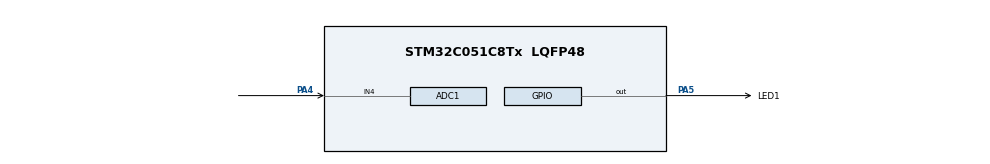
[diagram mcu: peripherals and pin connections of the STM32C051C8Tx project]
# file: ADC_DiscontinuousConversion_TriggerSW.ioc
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ADC1.Channel-0\#ChannelRegularConversion=ADC_CHANNEL_4
ADC1.Channel-1\#ChannelRegularConversion=ADC_CHANNEL_VREFINT
ADC1.ClockPrescaler=ADC_CLOCK_SYNC_PCLK_DIV4
ADC1.DiscontinuousConvMode=ENABLE
ADC1.NbrOfConversion=2
ADC1.NbrOfConversionFlag=1
ADC1.Overrun=ADC_OVR_DATA_OVERWRITTEN
ADC1.Rank-0\#ChannelRegularConversion=1
ADC1.Rank-1\#ChannelRegularConversion=2
ADC1.SamplingTime-0\#ChannelRegularConversion=ADC_SAMPLINGTIME_COMMON_1
ADC1.SamplingTime-1\#ChannelRegularConversion=ADC_SAMPLINGTIME_COMMON_1
ADC1.SamplingTimeCommon1=ADC_SAMPLETIME_160CYCLES_5
ADC1.SamplingTimeCommon2=ADC_SAMPLETIME_160CYCLES_5
ADC1.ScanConvMode=ADC_SCAN_ENABLE
ADC1.SelectedChannel=ADC_CHANNEL_4|ADC_CHANNEL_VREFINT
ADC1.Sequencer=FULLY_CONFIGURABLE
ADC1.master=1
Mcu.Family=STM32C0
Mcu.Name=STM32C051C8Tx
Mcu.Package=LQFP48
PA4.Mode=IN4
PA4.Signal=ADC1_IN4
PA5.GPIO_Label=LED1
PA5.Signal=GPIO_Output
ProjectManager.HeapSize=0x200
ProjectManager.StackSize=0x400
ProjectManager.TargetToolchain=EWARM V9.20
RCC.ADCFreq_Value=48000000
RCC.AHBFreq_Value=48000000
RCC.CortexFreq_Value=48000000
RCC.EXTERNAL_CLOCK_VALUE=12288000
RCC.HCLKFreq_Value=48000000
RCC.HSE_VALUE=8000000
RCC.HSISYSCLKDivider=RCC_HSI_DIV1
RCC.HSI_VALUE=48000000
RCC.LSE_VALUE=32768
RCC.SYSCLKFreq_VALUE=48000000
VP_ADC1_Vref_Input.Mode=IN-Vrefint
board=custom

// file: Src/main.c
/* USER CODE BEGIN Header */
/**
  ******************************************************************************
  * @file    Examples/ADC/ADC_DiscontinuousConversion_TriggerSW/Src/main.c
  * @author  MCD Application Team
  * @brief   Use ADC to convert a single channel at each SW start.
  *          Conversion performed using programming model: polling
  *          This example is based on the STM32C0xx ADC HAL API.
  ******************************************************************************
  * @attention
  *
  * <h2><center>&copy; Copyright (c) 2024 STMicroelectronics.
  * All rights reserved.</center></h2>
  *
  * This software component is licensed by ST under BSD 3-Clause license,
  * the "License"; You may not use this file except in compliance with the
  * License. You may obtain a copy of the License at:
  *                        opensource.org/licenses/BSD-3-Clause
  *
  ******************************************************************************
  */
/* USER CODE END Header */
#include "main.h"

/* USER CODE BEGIN PD */

/* Definitions of environment analog values */
  /* Value of analog reference voltage (Vref+), connected to analog voltage   */
  /* supply Vdda (unit: mV).                                                  */
  #define VDDA_APPLI                       (3300UL)

/* Definitions of data related to this example */
  /* Definition of ADCx conversions data table size */
  /* Size of array set to ADC sequencer number of ranks converted,            */
  /* to have a rank in each array address.                                    */
  #define ADC_CONVERTED_DATA_BUFFER_SIZE   (   2UL)

  /* Init variable out of expected ADC conversion data range */
  #define VAR_CONVERTED_DATA_INIT_VALUE    (__LL_ADC_DIGITAL_SCALE(LL_ADC_RESOLUTION_12B) + 1)

/* USER CODE END PD */

ADC_HandleTypeDef hadc1;

/* USER CODE BEGIN PV */

/* Variables for ADC conversion data */
__IO uint16_t uhADCxConvertedData[ADC_CONVERTED_DATA_BUFFER_SIZE]; /* ADC group regular conversion data */

/* Variables for ADC conversion data computation to physical values */
uint16_t uhADCxConvertedData_VoltageGPIO_mVolt = 0UL; /* Value of voltage calculated from ADC conversion data (unit: mV) */
uint16_t uhADCxConvertedData_VrefAnalog_mVolt  = 0UL; /* Value of analog reference voltage (Vref+), connected to analog voltage supply Vdda, calculated from ADC conversion data (unit: mV) */
uint16_t uhADCxConvertedData_VrefInt_mVolt     = 0UL; /* Value of internal voltage reference VrefInt calculated from ADC conversion data (unit: mV) */
/* USER CODE END PV */

void SystemClock_Config(void);
static void MX_GPIO_Init(void);
static void MX_ADC1_Init(void);

int main(void)
{

  /* USER CODE BEGIN 1 */
  uint32_t tmp_index;

  /* Initialize ADC group regular data buffer values */
  for (tmp_index = 0; tmp_index < ADC_CONVERTED_DATA_BUFFER_SIZE; tmp_index++)
  {
    uhADCxConvertedData[tmp_index] = VAR_CONVERTED_DATA_INIT_VALUE;
  }

  /* USER CODE END 1 */

  /* MCU Configuration--------------------------------------------------------*/

  /* Reset of all peripherals, Initializes the Flash interface and the Systick. */
  HAL_Init();

  /* Configure the system clock */
  SystemClock_Config();

  /* Initialize all configured peripherals */
  MX_GPIO_Init();
  MX_ADC1_Init();
  /* USER CODE BEGIN 2 */

  /* Initialize LED on board */
  BSP_LED_Init(LED4);

  /* Perform ADC calibration */
  if (HAL_ADCEx_Calibration_Start(&hadc1) != HAL_OK)
  {
    /* Calibration Error */
    Error_Handler();
  }

  /* USER CODE END 2 */

  /* Infinite loop */
  /* USER CODE BEGIN WHILE */
  while (1)
  {
    for (tmp_index = 0; tmp_index < ADC_CONVERTED_DATA_BUFFER_SIZE; tmp_index++)
    {
      /* Start ADC group regular conversion */
      if (HAL_ADC_Start(&hadc1) != HAL_OK)
      {
        /* ADC conversion start error */
        Error_Handler();
      }

      /* Wait for ADC conversion completed */
      if (HAL_ADC_PollForConversion(&hadc1, 10) != HAL_OK)
      {
        /* End Of Conversion flag not set on time */
        Error_Handler();
      }

      /* Retrieve ADC conversion data */
      uhADCxConvertedData[tmp_index] = HAL_ADC_GetValue(&hadc1);

      /* Toggle LED at each ADC conversion */
      BSP_LED_Toggle(LED4);
      HAL_Delay(LED_BLINK_SLOW);
    }

    /* Note: ADC group regular conversions data are stored into array         */
    /*       "uhADCxConvertedData"                                            */
    /*       (for debug: see variable content into watch window).             */

    /* Note: ADC conversion data are computed to physical values              */
    /*       into array "uhADCxConvertedData_VoltageGPIO_mVolt" using         */
    /*       ADC LL driver helper macro "__LL_ADC_CALC_DATA_TO_VOLTAGE()"     */
    /*       (for debug: see variable content with debugger)                  */

    /* For this example purpose, calculate analog reference voltage (Vref+) */
    /* from ADC conversion of internal voltage reference VrefInt.           */
    /* This voltage should correspond to value of literal "VDDA_APPLI".     */
    /* Note: This calculation can be performed when value of voltage Vref+  */
    /*       is unknown in the application                                  */
    /*       (This is not the case in this example due to target board      */
    /*       supplied by a LDO regulator providing a known constant voltage */
    /*       of value "VDDA_APPLI").                                        */
    /*       In typical case of Vref+ connected to Vdd, it allows to        */
    /*       deduce Vdd value.                                              */
    uhADCxConvertedData_VrefAnalog_mVolt = __LL_ADC_CALC_VREFANALOG_VOLTAGE(uhADCxConvertedData[1], LL_ADC_RESOLUTION_12B);

    /* Computation of ADC conversions raw data to physical values           */
    /* using LL ADC driver helper macro.                                    */
    uhADCxConvertedData_VoltageGPIO_mVolt = __LL_ADC_CALC_DATA_TO_VOLTAGE(uhADCxConvertedData_VrefAnalog_mVolt, uhADCxConvertedData[0], LL_ADC_RESOLUTION_12B);
    uhADCxConvertedData_VrefInt_mVolt     = __LL_ADC_CALC_DATA_TO_VOLTAGE(uhADCxConvertedData_VrefAnalog_mVolt, uhADCxConvertedData[1], LL_ADC_RESOLUTION_12B);

    /* USER CODE END WHILE */

  }
}

void SystemClock_Config(void)
{
  RCC_OscInitTypeDef RCC_OscInitStruct = {0};
  RCC_ClkInitTypeDef RCC_ClkInitStruct = {0};

  __HAL_FLASH_SET_LATENCY(FLASH_LATENCY_1);

  /** Initializes the RCC Oscillators according to the specified parameters
  * in the RCC_OscInitTypeDef structure.
  */
  RCC_OscInitStruct.OscillatorType = RCC_OSCILLATORTYPE_HSI;
  RCC_OscInitStruct.HSIState = RCC_HSI_ON;
  RCC_OscInitStruct.HSIDiv = RCC_HSI_DIV1;
  RCC_OscInitStruct.HSICalibrationValue = RCC_HSICALIBRATION_DEFAULT;
  if (HAL_RCC_OscConfig(&RCC_OscInitStruct) != HAL_OK)
  {
    Error_Handler();
  }

  /** Initializes the CPU, AHB and APB buses clocks
  */
  RCC_ClkInitStruct.ClockType = RCC_CLOCKTYPE_HCLK|RCC_CLOCKTYPE_SYSCLK
                              |RCC_CLOCKTYPE_PCLK1;
  RCC_ClkInitStruct.SYSCLKSource = RCC_SYSCLKSOURCE_HSI;
  RCC_ClkInitStruct.SYSCLKDivider = RCC_SYSCLK_DIV1;
  RCC_ClkInitStruct.AHBCLKDivider = RCC_HCLK_DIV1;
  RCC_ClkInitStruct.APB1CLKDivider = RCC_APB1_DIV1;

  if (HAL_RCC_ClockConfig(&RCC_ClkInitStruct, FLASH_LATENCY_1) != HAL_OK)
  {
    Error_Handler();
  }
}

static void MX_ADC1_Init(void)
{

  ADC_ChannelConfTypeDef sConfig = {0};

  /** Configure the global features of the ADC (Clock, Resolution, Data Alignment and number of conversion)
  */
  hadc1.Instance = ADC1;
  hadc1.Init.ClockPrescaler = ADC_CLOCK_SYNC_PCLK_DIV4;
  hadc1.Init.Resolution = ADC_RESOLUTION_12B;
  hadc1.Init.DataAlign = ADC_DATAALIGN_RIGHT;
  hadc1.Init.ScanConvMode = ADC_SCAN_ENABLE;
  hadc1.Init.EOCSelection = ADC_EOC_SINGLE_CONV;
  hadc1.Init.LowPowerAutoWait = DISABLE;
  hadc1.Init.LowPowerAutoPowerOff = DISABLE;
  hadc1.Init.ContinuousConvMode = DISABLE;
  hadc1.Init.NbrOfConversion = 2;
  hadc1.Init.DiscontinuousConvMode = ENABLE;
  hadc1.Init.ExternalTrigConv = ADC_SOFTWARE_START;
  hadc1.Init.ExternalTrigConvEdge = ADC_EXTERNALTRIGCONVEDGE_NONE;
  hadc1.Init.DMAContinuousRequests = DISABLE;
  hadc1.Init.Overrun = ADC_OVR_DATA_OVERWRITTEN;
  hadc1.Init.SamplingTimeCommon1 = ADC_SAMPLETIME_160CYCLES_5;
  hadc1.Init.SamplingTimeCommon2 = ADC_SAMPLETIME_160CYCLES_5;
  hadc1.Init.OversamplingMode = DISABLE;
  hadc1.Init.TriggerFrequencyMode = ADC_TRIGGER_FREQ_HIGH;
  if (HAL_ADC_Init(&hadc1) != HAL_OK)
  {
    Error_Handler();
  }

  /** Configure Regular Channel
  */
  sConfig.Channel = ADC_CHANNEL_4;
  sConfig.Rank = ADC_REGULAR_RANK_1;
  sConfig.SamplingTime = ADC_SAMPLINGTIME_COMMON_1;
  if (HAL_ADC_ConfigChannel(&hadc1, &sConfig) != HAL_OK)
  {
    Error_Handler();
  }

  /** Configure Regular Channel
  */
  sConfig.Channel = ADC_CHANNEL_VREFINT;
  sConfig.Rank = ADC_REGULAR_RANK_2;
  if (HAL_ADC_ConfigChannel(&hadc1, &sConfig) != HAL_OK)
  {
    Error_Handler();
  }

}

static void MX_GPIO_Init(void)
{
  GPIO_InitTypeDef GPIO_InitStruct = {0};

  /* GPIO Ports Clock Enable */
  __HAL_RCC_GPIOA_CLK_ENABLE();

  /*Configure GPIO pin Output Level */
  HAL_GPIO_WritePin(LED1_GPIO_Port, LED1_Pin, GPIO_PIN_RESET);

  /*Configure GPIO pin : LED1_Pin */
  GPIO_InitStruct.Pin = LED1_Pin;
  GPIO_InitStruct.Mode = GPIO_MODE_OUTPUT_PP;
  GPIO_InitStruct.Pull = GPIO_NOPULL;
  GPIO_InitStruct.Speed = GPIO_SPEED_FREQ_LOW;
  HAL_GPIO_Init(LED1_GPIO_Port, &GPIO_InitStruct);

}

void Error_Handler(void)
{
  /* USER CODE BEGIN Error_Handler_Debug */
  /* User can add his own implementation to report the HAL error return state */

  /* Turn on LED and remain in infinite loop */
  while (1)
  {
    BSP_LED_On(LED4);
  }
  /* USER CODE END Error_Handler_Debug */
}
